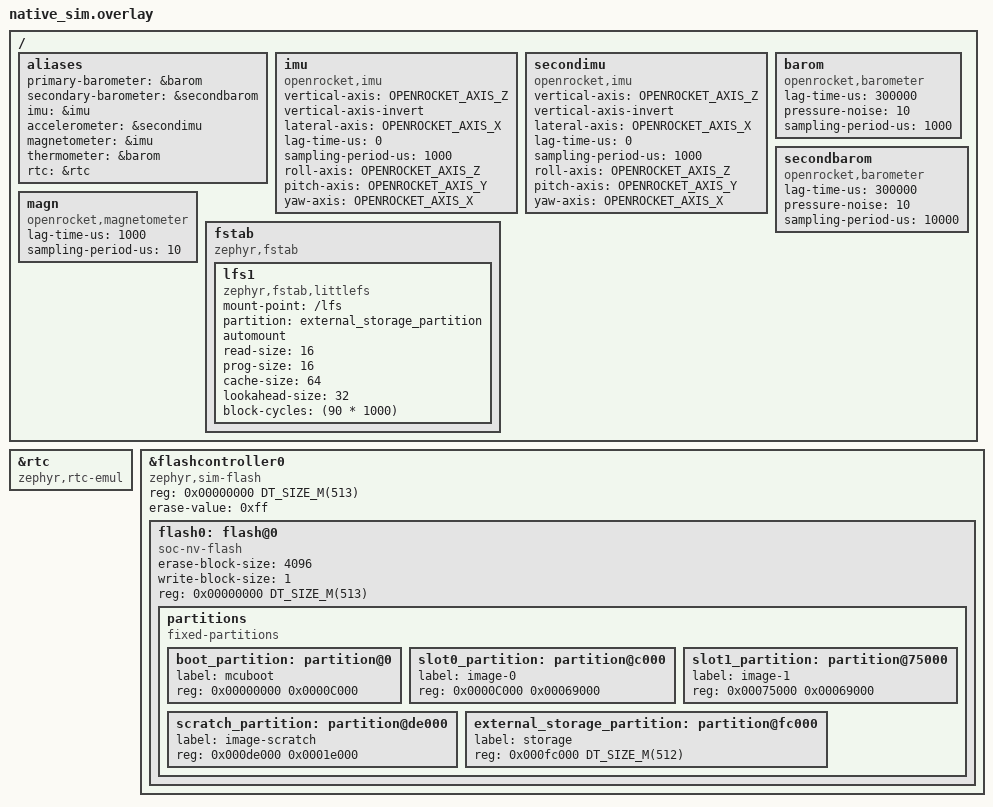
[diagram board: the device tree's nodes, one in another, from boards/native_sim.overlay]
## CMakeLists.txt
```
#-------------------------------------------------------------------------------
# Backplane Sensor Module Application
#
# Copyright (c) 2023 Launch Initiative
# SPDX-License-Identifier: Apache-2.0

set(FSW_ROOT ${CMAKE_CURRENT_SOURCE_DIR}/../../..)
include(${FSW_ROOT}/cmake/Autocoders.cmake)
include(${FSW_ROOT}/cmake/Snippets.cmake)

list(APPEND SNIPPETS
"bpl-networking"
"cpp"
)

AddSnippets(${SNIPPETS})


list(APPEND CONF_FILE ${CMAKE_CURRENT_SOURCE_DIR}/core.conf)

if (DEBUG)
    message(STATUS "Adding debug configuration")
    AddDebugSnippets()
    list(APPEND CONF_FILE ${CMAKE_CURRENT_SOURCE_DIR}/debug.conf)
endif ()

if (BOARD STREQUAL "native_sim")
    if (UNIX AND NOT APPLE)
        message(STATUS "Adding simulation configuration")
        AddSimSnippets()
        list(APPEND CONF_FILE ${CMAKE_CURRENT_SOURCE_DIR}/sim.conf)
    else ()
        message(FATAL_ERROR "Simulation is only supported on Linux systems")
    endif ()
endif ()

cmake_minimum_required(VERSION 3.13.1)
find_package(Zephyr REQUIRED HINTS $ENV{ZEPHYR_BASE})

project(sensor-module LANGUAGES C CXX)

FILE(GLOB SOURCES src/*.c src/*.cpp)
target_include_directories(app PRIVATE include)
target_sources(app PRIVATE ${SOURCES})

AutocodeTypes(${CMAKE_SOURCE_DIR}/ac/types.yaml)
AutocodeNetworkDefinitions()
add_dependencies(app ac_net_defs ac_types)
```

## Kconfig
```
# Copyright (c) 2024 Launch Initiative
# SPDX-License-Identifier: Apache-2.0

menu "Zephyr"
source "Kconfig.zephyr"
endmenu

module = APP_SENSOR_MODULE
module-str = APP_SENSOR_MODULE
source "subsys/logging/Kconfig.template.log_config"

config MODULE_ID
    int "Module ID number"
    default 1
    help
      The module ID to use as the fourth octet in the IP address.
```

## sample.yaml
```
sample:
  description: Sensor Module
  name: sensor-module
common:
  build_only: true
  integration_platforms:
    - sensor_module
tests:
  backplane.sensor_module.default: {}
# Disabled for now due to RAM constraints
#  backplane.sensor_module.debug:
#    extra_overlay_confs:
#      - sim.conf
```

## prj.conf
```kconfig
# Copyright (c) 2024 RIT Launch Initiative
# SPDX-License-Identifier: Apache-2.0

# CPP
CONFIG_CPP=y
CONFIG_REQUIRES_FULL_LIBCPP=y
CONFIG_STD_CPP20=y

CONFIG_F_CORE=y
CONFIG_CBPRINTF_FP_SUPPORT=y

# Filesystem
CONFIG_FILE_SYSTEM=y
CONFIG_FLASH_MAP=y
CONFIG_FLASH=y
# OS
CONFIG_POLL=y
CONFIG_MAIN_STACK_SIZE=1024
CONFIG_STACK_USAGE=y

CONFIG_TIMESLICING=y
CONFIG_TIMESLICE_SIZE=50000
CONFIG_TIMESLICE_PRIORITY=0
CONFIG_THREAD_STACK_INFO=y

CONFIG_DYNAMIC_THREAD=y
# Max stack size for dynamic threads
CONFIG_DYNAMIC_THREAD_STACK_SIZE=512
CONFIG_DYNAMIC_THREAD_POOL_SIZE=4
CONFIG_LOG=y

# Networking
CONFIG_NETWORKING=y
CONFIG_NET_ARP_TABLE_SIZE=4
CONFIG_NET_CONTEXT_RCVTIMEO=y
CONFIG_NET_DEFAULT_IF_ETHERNET=y
CONFIG_NET_DRIVERS=y
CONFIG_NET_IPV4=y
CONFIG_NET_IPV6=n
CONFIG_NET_L2_ETHERNET=y
CONFIG_NET_L2_ETHERNET_MGMT=y
CONFIG_NET_MAX_CONN=10
CONFIG_NET_SOCKETS=y
CONFIG_NET_STATISTICS=y

# RNG (Needed for networking)
CONFIG_ENTROPY_GENERATOR=y
CONFIG_TEST_RANDOM_GENERATOR=y # TODO: See if its worth using STM32 HW RNG to remove warning

# IO
CONFIG_I2C=y
CONFIG_SPI=y
CONFIG_SENSOR=y
```

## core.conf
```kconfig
# Copyright (c) 2024 RIT Launch Initiative
# SPDX-License-Identifier: Apache-2.0

CONFIG_F_CORE=y
CONFIG_F_CORE_DEVICE=y
CONFIG_F_CORE_SENSOR=y
CONFIG_F_CORE_NET=y
CONFIG_F_CORE_OS=y
CONFIG_F_CORE_UTILS=y

CONFIG_CBPRINTF_FP_SUPPORT=y

# OS
CONFIG_POLL=y
CONFIG_MAIN_STACK_SIZE=2048
CONFIG_STACK_USAGE=y

CONFIG_TIMESLICING=y
CONFIG_TIMESLICE_SIZE=20
CONFIG_TIMESLICE_PRIORITY=0
CONFIG_THREAD_STACK_INFO=y

CONFIG_DYNAMIC_THREAD=y
# Max stack size for dynamic threads
CONFIG_DYNAMIC_THREAD_STACK_SIZE=4096
CONFIG_DYNAMIC_THREAD_POOL_SIZE=3
CONFIG_LOG=y
CONFIG_EVENTS=y

# IO
CONFIG_I2C=y
CONFIG_SPI=y
CONFIG_SENSOR=y
```

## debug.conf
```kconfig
# Copyright (c) 2024 Launch Initiative
# SPDX-License-Identifier: Apache-2.0

CONFIG_APP_SENSOR_MODULE_LOG_LEVEL_DBG=y
```

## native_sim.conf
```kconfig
# Sensors
CONFIG_OPENROCKET_LOG_LEVEL_DBG=y
CONFIG_OPENROCKET_SENSORS=y
CONFIG_OPENROCKET_DATA_FILE="../../../data/orksim_csv/omen.csv"
CONFIG_OPENROCKET_MS_BEFORE_LAUNCH=1000
CONFIG_OPENROCKET_SCALAR_TYPE_DOUBLE=y
CONFIG_OPENROCKET_EVENT_LOG=y
CONFIG_OPENROCKET_IMU=y
CONFIG_OPENROCKET_BAROMETER=y
```

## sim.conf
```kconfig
# Sensors
CONFIG_OPENROCKET_SENSORS=y
CONFIG_OPENROCKET_DATA_FILE="../../../data/orksim_csv/l1.csv"
CONFIG_OPENROCKET_SCALAR_TYPE_DOUBLE=y
CONFIG_OPENROCKET_EVENT_LOG=y
CONFIG_OPENROCKET_IMU=y
CONFIG_OPENROCKET_BAROMETER=y
CONFIG_OPENROCKET_MANUAL_LAUNCH_TRIGGER=y

CONFIG_RTC=y
CONFIG_RTC_EMUL=y

CONFIG_SYS_CLOCK_TICKS_PER_SEC=10000
CONFIG_DEBUG=y
```

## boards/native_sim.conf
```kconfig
# Sensors
#CONFIG_OPENROCKET_NOISE=y
#CONFIG_OPENROCKET_NOISE_SEED=0

CONFIG_OPENROCKET_SENSORS=y
CONFIG_OPENROCKET_DATA_FILE="../../../data/orksim_csv/omen.csv"
CONFIG_OPENROCKET_MS_BEFORE_LAUNCH=150000
CONFIG_OPENROCKET_SCALAR_TYPE_DOUBLE=y
CONFIG_OPENROCKET_EVENT_LOG=y
CONFIG_OPENROCKET_IMU=y
CONFIG_OPENROCKET_BAROMETER=y

CONFIG_RTC_EMUL=y
```

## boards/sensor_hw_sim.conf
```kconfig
# Sensors
#CONFIG_OPENROCKET_NOISE=y
#CONFIG_OPENROCKET_NOISE_SEED=0

CONFIG_OPENROCKET_SENSORS=y
CONFIG_OPENROCKET_DATA_FILE="../../../data/orksim_csv/l1.csv"
CONFIG_OPENROCKET_MS_BEFORE_LAUNCH=10000
CONFIG_OPENROCKET_SCALAR_TYPE_DOUBLE=y
CONFIG_OPENROCKET_EVENT_LOG=y
CONFIG_OPENROCKET_IMU=y
CONFIG_OPENROCKET_BAROMETER=y
CONFIG_OPENROCKET_MANUAL_LAUNCH_TRIGGER=y

CONFIG_CONSOLE=y
CONFIG_CONSOLE_SUBSYS=y
CONFIG_SERIAL=y
CONFIG_UART_CONSOLE=y
```

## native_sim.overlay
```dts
/ {
	aliases {
		primary-barometer = &barom;
		secondary-barometer = &barom;
		imu = &imu;
		accelerometer = &imu;
		magnetometer = &imu;
		thermometer = &barom;
	};

    imu: imu {
        status = "okay";
        compatible = "openrocket,imu";
        vertical-axis = "OPENROCKET_AXIS_Z";
        vertical-axis-invert;
        lateral-axis = "OPENROCKET_AXIS_X";
        lag-time-us = <1000>;
        sampling-period-us = <10>;

        roll-axis = "OPENROCKET_AXIS_Z";
        pitch-axis = "OPENROCKET_AXIS_Y";
        yaw-axis = "OPENROCKET_AXIS_X";
    };

    barom: barom {
        status = "okay";
        compatible = "openrocket,barometer";
        lag-time-us = <1000>;
        sampling-period-us = <10>;
    };
};
```

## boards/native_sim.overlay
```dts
/ {
	aliases {
		primary-barometer = &barom;
		secondary-barometer = &secondbarom;
		imu = &imu;
		accelerometer = &secondimu;
		magnetometer = &imu;
		thermometer = &barom;
		rtc = &rtc;
	};

    imu: imu {
        status = "okay";
        compatible = "openrocket,imu";
        vertical-axis = "OPENROCKET_AXIS_Z";
        vertical-axis-invert;
        lateral-axis = "OPENROCKET_AXIS_X";
        lag-time-us = <0>;
        sampling-period-us = <1000>;

        roll-axis = "OPENROCKET_AXIS_Z";
        pitch-axis = "OPENROCKET_AXIS_Y";
        yaw-axis = "OPENROCKET_AXIS_X";
    };


    secondimu: secondimu {
        status = "okay";
        compatible = "openrocket,imu";
        vertical-axis = "OPENROCKET_AXIS_Z";
        vertical-axis-invert;
        lateral-axis = "OPENROCKET_AXIS_X";
        lag-time-us = <0>;
        sampling-period-us = <1000>;

        roll-axis = "OPENROCKET_AXIS_Z";
        pitch-axis = "OPENROCKET_AXIS_Y";
        yaw-axis = "OPENROCKET_AXIS_X";
    };


    barom: barom {
        status = "okay";
        compatible = "openrocket,barometer";
        lag-time-us = <300000>; // from grim analysis
		pressure-noise = <10>;
        sampling-period-us = <1000>;
    };

    secondbarom: secondbarom {
        status = "okay";
        compatible = "openrocket,barometer";
        lag-time-us = <300000>; // from grim analysis
		pressure-noise = <10>;
		sampling-period-us = <10000>;
    };

    magn: magn {
        status = "okay";
        compatible = "openrocket,magnetometer";
        lag-time-us = <1000>;
		sampling-period-us = <10>;
    };

	fstab {
		compatible = "zephyr,fstab";
		lfs1: lfs1 {
			compatible = "zephyr,fstab,littlefs";
			mount-point = "/lfs";
			partition = <&external_storage_partition>;
			automount;

			// the binding reccomends defaults for these
			read-size = <16>;
			prog-size = <16>;
			cache-size = <64>; // may need to grow for optimization
			lookahead-size = <32>;
			block-cycles = <(90 * 1000)>;
			// the datasheet gives 100K P-E cycles
			// NOTE: this seems to default to 512 for the mounted filesystem
			// anyway
		};
	};
};

&rtc {
	status = "okay";
	compatible = "zephyr,rtc-emul";
};

&flashcontroller0 {
	status = "okay";
	compatible = "zephyr,sim-flash";
	reg = <0x00000000 DT_SIZE_M(513)>;

	#address-cells = <1>;
	#size-cells = <1>;
	erase-value = <0xff>;

	flash0: flash@0 {
		status = "okay";
		compatible = "soc-nv-flash";
		erase-block-size = <4096>;
		write-block-size = <1>;
		reg = <0x00000000 DT_SIZE_M(513)>; // builtin stuff + external flash simulation

		partitions {
			compatible = "fixed-partitions";
			#address-cells = <1>;
			#size-cells = <1>;

			boot_partition: partition@0 {
				label = "mcuboot";
				reg = <0x00000000 0x0000C000>;
			};
			slot0_partition: partition@c000 {
				label = "image-0";
				reg = <0x0000C000 0x00069000>;
			};
			slot1_partition: partition@75000 {
				label = "image-1";
				reg = <0x00075000 0x00069000>;
			};
			scratch_partition: partition@de000 {
				label = "image-scratch";
				reg = <0x000de000 0x0001e000>;
			};
			external_storage_partition: partition@fc000 {
				label = "storage";
				reg = <0x000fc000 DT_SIZE_M(512)>;
			};
		};
	};
};
```

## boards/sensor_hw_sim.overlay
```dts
/ {
	aliases {
		primary-barometer = &barom;
		secondary-barometer = &secondbarom;
		imu = &imu;
		accelerometer = &secondimu;
		magnetometer = &imu;
		thermometer = &barom;
	};

    imu: imu {
        status = "okay";
        compatible = "openrocket,imu";
        vertical-axis = "OPENROCKET_AXIS_Z";
        vertical-axis-invert;
        lateral-axis = "OPENROCKET_AXIS_X";
        lag-time-us = <0>;
        sampling-period-us = <1000>;

        roll-axis = "OPENROCKET_AXIS_Z";
        pitch-axis = "OPENROCKET_AXIS_Y";
        yaw-axis = "OPENROCKET_AXIS_X";
    };


    secondimu: secondimu {
        status = "okay";
        compatible = "openrocket,imu";
        vertical-axis = "OPENROCKET_AXIS_Z";
        vertical-axis-invert;
        lateral-axis = "OPENROCKET_AXIS_X";
        lag-time-us = <0>;
        sampling-period-us = <1000>;

        roll-axis = "OPENROCKET_AXIS_Z";
        pitch-axis = "OPENROCKET_AXIS_Y";
        yaw-axis = "OPENROCKET_AXIS_X";
    };


    barom: barom {
        status = "okay";
        compatible = "openrocket,barometer";
        lag-time-us = <300000>; // from grim analysis
		pressure-noise = <10>;
        sampling-period-us = <1000>;
    };

    secondbarom: secondbarom {
        status = "okay";
        compatible = "openrocket,barometer";
        lag-time-us = <300000>; // from grim analysis
		pressure-noise = <10>;
		sampling-period-us = <10000>;
    };

    magn: magn {
        status = "okay";
        compatible = "openrocket,magnetometer";
        lag-time-us = <1000>;
		sampling-period-us = <10>;
    };
};
```

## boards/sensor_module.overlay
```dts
/ {
	aliases {
		primary-barometer = &ms5611;
		secondary-barometer = &bmp388;
		imu = &lsm6dsl;
		accelerometer = &adxl375;
		magnetometer = &lis3mdl;
		thermometer = &tmp117;

		rs485-uart = &uart5;
		rs485-de = &de_hack;
		rtc = &rtc;
	};
};
```

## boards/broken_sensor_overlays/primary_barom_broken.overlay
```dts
&barom{
    broken;
};
```

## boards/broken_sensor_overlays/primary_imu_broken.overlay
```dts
&imu{
    broken;
};
```

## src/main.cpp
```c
/*
* Copyright (c) 2024 RIT Launch Initiative
 *
 * SPDX-License-Identifier: Apache-2.0
 */
#include "c_sensor_module.h"

#include <f_core/os/n_rtos.h>
#ifdef CONFIG_ARCH_POSIX
#include <nsi_main.h>
#include <signal.h>
#endif

#ifdef CONFIG_ARCH_POSIX
static volatile sig_atomic_t shutdownRequested = 0;

static void NativeSimSignalHandler(int) { shutdownRequested = 1; }
#endif

int main() {
    static CSensorModule sensorModule{};

    sensorModule.AddTenantsToTasks();
    sensorModule.AddTasksToRtos();
    sensorModule.SetupCallbacks();

    NRtos::StartRtos();

#ifdef CONFIG_ARCH_POSIX
    signal(SIGINT, NativeSimSignalHandler);
    signal(SIGTERM, NativeSimSignalHandler);

    while (!shutdownRequested) {
        k_sleep(K_MSEC(100));
    }

    NRtos::StopRtos();
    sensorModule.Cleanup();
    nsi_exit(0);
#endif

    return 0;
}
```

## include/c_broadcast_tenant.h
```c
#ifndef C_BROADCAST_TENANT_H
#define C_BROADCAST_TENANT_H

#include <f_core/os/c_tenant.h>

#include <f_core/net/network/c_ipv4.h>
#include <f_core/net/transport/c_udp_socket.h>

class CBroadcastTenant : public CTenant {
public:
    explicit CBroadcastTenant(const char* name, const char *ipStr, const uint16_t srcPort, const uint16_t dstPort)
        : CTenant(name), ip(CIPv4{ipStr}), udp(CUdpSocket{ip, srcPort, dstPort})
    {
    }

    ~CBroadcastTenant() override = default;

    void Startup() override;

    void PostStartup() override;

    void Run() override;

private:
    CIPv4 ip;
    CUdpSocket udp;
};



#endif //C_BROADCAST_TENANT_H
```

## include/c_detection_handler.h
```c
#pragma once

// All in one holder for all the detection we do
#include "f_core/utils/debouncer.hpp"
#include "f_core/utils/linear_fit.hpp"
#include "flight.hpp"

#include <f_core/messaging/c_message_port.h>
#include <f_core/n_alerts.h>
#include <n_autocoder_types.h>

class CDetectionHandler {
  public:
    struct SensorWorkings {
        bool primaryAccOk;
        bool secondaryAccOk;
        bool primaryBarometerOk;
        bool secondaryBarometerOk;
    };

    static constexpr std::size_t BAROM_VELOCITY_FINDER_WINDOW_SIZE = 10; // @100hz, 0.1 second window.
    using VelocityFinder = CRollingSum<LinearFitSample<double>, BAROM_VELOCITY_FINDER_WINDOW_SIZE>;

    // Boost Detectors
    using AccBoostDetector = CDebouncer<ThresholdDirection::Over, double>;
    using BaromBoostDetector = CDebouncer<ThresholdDirection::Over, double>;

    using BaromNoseoverDetector = CDebouncer<ThresholdDirection::Under, double>;
    using BaromGroundDetector = CDebouncer<ThresholdDirection::Under, double>;
    CDetectionHandler(SensorModulePhaseController& controller, CMessagePort<NAlerts::AlertPacket>& alertMessagePort);

    SensorModulePhaseController& controller;
    AccBoostDetector primaryImuBoostSquaredDetector;
    AccBoostDetector secondaryImuBoostSquaredDetector;

    VelocityFinder primaryBaromVelocityFinder;
    VelocityFinder secondaryBaromVelocityFinder;

    BaromNoseoverDetector primaryBaromNoseoverDetector;
    BaromNoseoverDetector secondaryBaromNoseoverDetector;

    BaromGroundDetector primaryBaromGroundDetector;
    BaromGroundDetector secondaryBaromGroundDetector;

    static constexpr uint64_t BOOST_NOT_YET_HAPPENED = ~0;
    uint64_t boost_detected_time = BOOST_NOT_YET_HAPPENED;

    static constexpr uint32_t alertResendCycles = 20;
    uint32_t boostAlertResendsRemaining = 0;
    uint32_t landedAlertResendsRemaining = alertResendCycles;

    // Rebroadcast the landed alert once GroundHit occurs. Covers both the
    // barometer and timer paths, and survives UDP loss like the boost alert.
    void ServiceLandedAlert();

    /**
     * Process sensor information 
     * @param uptime uptime in milliseconds of the system
     * @param data sensor data from Sensing Tenant
     * @param workings a description of which sensors were read correctly
     */
    void HandleData(const uint64_t uptime, const NTypes::SensorData& data, const SensorWorkings& workings);

    /**
     * Process sensor information before boost has been detected
     * @param t_plus_ms milliseconds since boost
     * @param data sensor data from Sensing Tenant
     * @param workings a description of which sensors were read correctly
     */
    void HandleBoost(const uint64_t uptime, const NTypes::SensorData& data, const SensorWorkings& workings);
    /**
     * Process sensor information before the noseover has been reached
     * @param t_plus_ms milliseconds since boost
     * @param data sensor data from Sensing Tenant
     * @param workings a description of which sensors were read correctly
     */
    void HandleNoseover(const uint32_t t_plus_ms, const NTypes::SensorData& data, const SensorWorkings& workings);
    /**
     * Process sensor information before the ground has been hit
     * @param t_plus_ms milliseconds since boost
     * @param data sensor data from Sensing Tenant
     * @param workings a description of which sensors were read correctly
     */
    void HandleGround(const uint32_t t_plus_ms, const NTypes::SensorData& data, const SensorWorkings& workings);

    bool FlightOccurring() {
        // int uptime = k_uptime_get();
        // static constexpr int START_TIME = 10000; // 10 seconds
        // static constexpr int END_TIME = 30000; // 30 seconds

        // return START_TIME <= uptime && uptime <= END_TIME;
        return controller.HasEventOccurred(Events::Boost) && !controller.HasEventOccurred(Events::GroundHit);
    }

    bool FlightFinished() {
        // int uptime = k_uptime_get();
        // return uptime >= 30000;

        return controller.HasEventOccurred(Events::GroundHit);
    }

    /**
     * Whether or not the phase detector needs more data. True before ground hit, false after
     * @return true if the detection system wants more data, false if we're all finished
     */
    bool ContinueCollecting();

  private:
    static constexpr NAlerts::AlertPacket boostNotification = {'L', 'A', 'U', 'N', 'C', 'H', 'b'};
    static constexpr NAlerts::AlertPacket noseoverNotification = {'L', 'A', 'U', 'N', 'C', 'H', 'n'};
    static constexpr NAlerts::AlertPacket landedNotification = {'L', 'A', 'U', 'N', 'C', 'H', 'l'};

    CMessagePort<NAlerts::AlertPacket>& alertMessagePort;
};
```

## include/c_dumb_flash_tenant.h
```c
#ifndef C_DUMB_FLASH_TENANT_H
#define C_DUMB_FLASH_TENANT_H
#include <f_core/messaging/c_message_port.h>
#include <f_core/os/c_runnable_tenant.h>
#include <f_core/os/c_tenant.h>
#include <f_core/utils/c_soft_timer.h>
#include <n_autocoder_types.h>
#include <zephyr/drivers/flash.h>
#include <zephyr/logging/log.h>

class CDumbFlashTenant : public CRunnableTenant {
  public:
    static constexpr size_t ERASE_SIZE = 4096;
    static constexpr size_t ELEMENT_SIZE = sizeof(NTypes::TimestampedSensorData);
    using Element = NTypes::TimestampedSensorData;

    CDumbFlashTenant(const char *name, const struct device *device, size_t flash_offset, size_t partition_size,
                     CMessagePort<NTypes::TimestampedSensorData> &port);

    void Startup() override;
    void Run();

  private:
    const struct device *device;
    size_t flash_offset;
    size_t offset_into_partition = 0;
    size_t partition_size;
    CMessagePort<NTypes::TimestampedSensorData> &port;
};

#endif
```

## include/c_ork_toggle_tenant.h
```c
#pragma once

#include <f_core/net/network/c_ipv4.h>
#include <f_core/net/transport/c_udp_socket.h>
#include <f_core/os/c_runnable_tenant.h>

class COrkToggleTenant : public CRunnableTenant {
  public:
    /**
     * @param name Tenant name
     * @param ipStr IP address to bind the UDP socket to
     * @param port UDP port used to receive launch trigger packets
     */
    COrkToggleTenant(const char* name, const char* ipStr, int port);

    /**
     * See parent docs
     */
    void Run() override;

  private:
    CUdpSocket udp;
    int port;
};
```

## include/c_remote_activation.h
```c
#ifndef C_REMOTE_ACTIVATION_TENANT_H
#define C_REMOTE_ACTIVATION_TENANT_H

#include <f_core/net/network/c_ipv4.h>
#include <f_core/net/transport/c_udp_socket.h>
#include <f_core/os/c_tenant.h>
#include <zephyr/drivers/gpio.h>

class CRemoteActivationTenant : public CTenant {
public:
    explicit CRemoteActivationTenant(const char* name, const gpio_dt_spec &pin)
        : CTenant(name), ip(CIPv4{"10.3.2.1"}), udp(CUdpSocket{ip, commandPort, commandPort}), pin(pin)
    {
    }

    ~CRemoteActivationTenant() override = default;

    void Startup() override;

    void PostStartup() override;

    void Run() override;

private:
    static constexpr uint16_t commandPort = 13001;

    CIPv4 ip;
    CUdpSocket udp;
    const gpio_dt_spec &pin;
};


#endif //C_REMOTE_ACTIVATION_TENANT_H
```

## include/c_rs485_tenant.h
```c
#ifndef C_RS485_TENANT_H
#define C_RS485_TENANT_H

#include <f_core/net/device/c_rs485.h>
#include <f_core/os/c_tenant.h>

#include <zephyr/drivers/gpio.h>


class CRs485Tenant : public CTenant {
public:
  CRs485Tenant(const char* name)
    : CTenant(name)
  {
  }

  void Startup() override;

  void PostStartup() override;

  void Run() override;

private:
  // CRs485 &rs485{DEVICE_DT_GET(DT_ALIAS(rs485_uart)), GPIO_DT_SPEC_GET(de_hack, leds)};;

};



#endif //C_RS485_TENANT_H
```

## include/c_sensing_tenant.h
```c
#pragma once

#include "c_detection_handler.h"
#include "f_core/device/c_rtc.h"

#include <array>
#include <f_core/device/sensor/c_accelerometer.h>
#include <f_core/device/sensor/c_barometer.h>
#include <f_core/device/sensor/c_gyroscope.h>
#include <f_core/device/sensor/c_magnetometer.h>
#include <f_core/device/sensor/c_temperature_sensor.h>
#include <f_core/messaging/c_message_port.h>
#include <f_core/os/c_runnable_tenant.h>
#include <n_autocoder_types.h>
#include <zephyr/device.h>

class CSensorDevice;

class CSensingTenant : public CRunnableTenant {
  public:
    explicit CSensingTenant(const char *name, CMessagePort<NTypes::SensorData> &dataToBroadcast,
                            CMessagePort<NTypes::LoRaBroadcastSensorData> &downlinkDataToBroadcast,
                            CMessagePort<NTypes::TimestampedSensorData> &dataToLog, CDetectionHandler &handler);
    ~CSensingTenant() override = default;

    void Startup() override;
    void PostStartup() override;
    void Run() override;

  private:
    CMessagePort<NTypes::SensorData> &dataToBroadcast;
    CMessagePort<NTypes::TimestampedSensorData> &dataToLog;
    CMessagePort<NTypes::LoRaBroadcastSensorData> &dataToDownlink;

    CDetectionHandler &detectionHandler;
    // Sensor instances
    CAccelerometer imuAccelerometer;
    CGyroscope imuGyroscope;
    CBarometer primaryBarometer;
    CBarometer secondaryBarometer;
    CAccelerometer accelerometer;
    CTemperatureSensor thermometer;
    CMagnetometer magnetometer;

    std::array<CSensorDevice *, 7> sensors;

    CRtc rtc{*DEVICE_DT_GET(DT_ALIAS(rtc))};

    void sendDownlinkData(const NTypes::SensorData &data);

    void calibrateADXL375();
};
```

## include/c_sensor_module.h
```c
#pragma once

#include "c_sensing_tenant.h"
#include "flight.hpp"
#ifdef CONFIG_OPENROCKET_MANUAL_LAUNCH_TRIGGER
#include "c_ork_toggle_tenant.h"
#endif

// F-Core Includes
#include <f_core/c_project_configuration.h>
#include <f_core/device/c_rtc.h>
#include <f_core/messaging/c_message_port.h>
#include <f_core/n_alerts.h>
#include <f_core/net/application/c_udp_broadcast_tenant.h>
#include <f_core/os/c_task.h>
#include <f_core/os/flight_log.hpp>
#include <f_core/os/tenants/c_datalogger_tenant.h>
#include <n_autocoder_network_defs.h>
#include <n_autocoder_types.h>
#include <zephyr/fs/littlefs.h>

class CSensorModule : public CProjectConfiguration {
  public:
    /**
     * Constructor
     */
    CSensorModule();

    /**
     * See parent docs
     */
    void AddTenantsToTasks() override;

    /**
     * See parent docs
     */
    void AddTasksToRtos() override;

    /**
     * See parent docs
     */
    void SetupCallbacks() override;

    /**
    * Cleanup
    */
    void Cleanup() { dataLoggerTenant.Cleanup(); }

  private:
    std::string ipAddrStr = CREATE_IP_ADDR(NNetworkDefs::SENSOR_MODULE_IP_ADDR_BASE, 1, CONFIG_MODULE_ID);
    const char* sntpServerAddr = "10.2.1.1"; // TODO: Maybe we should look into hostnames?

    static constexpr int telemetryBroadcastPort = NNetworkDefs::SENSOR_MODULE_TELEMETRY_PORT;
    static constexpr int telemetryDownlinkPort = NNetworkDefs::SENSOR_MODULE_DOWNLINK_DATA_PORT;
    static constexpr int alertPort = NNetworkDefs::ALERT_PORT;
#ifdef CONFIG_OPENROCKET_MANUAL_LAUNCH_TRIGGER
    static constexpr int orkLaunchTriggerPort = NNetworkDefs::SENSOR_MODULE_ORK_LAUNCH_TRIGGER_PORT;
#endif

    // Devices
    CRtc rtc{*DEVICE_DT_GET(DT_ALIAS(rtc))};

    // Message Ports
    CMessagePort<NTypes::SensorData>& sensorDataBroadcastMessagePort;
    CMessagePort<NTypes::LoRaBroadcastSensorData>& downlinkMessagePort;
    CMessagePort<NTypes::TimestampedSensorData>& sensorDataLogMessagePort;
    CMessagePort<NAlerts::AlertPacket>& alertMessagePort;

    CFlightLog flight_log;
    SensorModulePhaseController controller{sourceNames, eventNames, timerEvents, deciders, NULL};
    CDetectionHandler detectionHandler{controller, alertMessagePort};

    // Tenants
    CSensingTenant sensingTenant{"Sensing Tenant", sensorDataBroadcastMessagePort, downlinkMessagePort,
                                 sensorDataLogMessagePort, detectionHandler};
    CUdpBroadcastTenant<NTypes::SensorData> broadcastTenant{"Broadcast Tenant", ipAddrStr.c_str(),
                                                            telemetryBroadcastPort, telemetryBroadcastPort,
                                                            sensorDataBroadcastMessagePort};
    CUdpBroadcastTenant<NTypes::LoRaBroadcastSensorData> downlinkTelemTenant{
        "Telemetry Downlink Tenant", ipAddrStr.c_str(), telemetryDownlinkPort, telemetryDownlinkPort,
        downlinkMessagePort};
    CUdpBroadcastTenant<NAlerts::AlertPacket> udpAlertTenant{"UDP Alert Tenant", ipAddrStr.c_str(), alertPort,
                                                             alertPort, alertMessagePort};
    CDataLoggerTenant<NTypes::TimestampedSensorData> dataLoggerTenant{"Data Logger Tenant",
                                                                      "/lfs/sensor_module_data.bin",
                                                                      LogMode::Growing,
                                                                      0,
                                                                      sensorDataLogMessagePort,
                                                                      K_SECONDS(3),
                                                                      64};
#ifdef CONFIG_OPENROCKET_MANUAL_LAUNCH_TRIGGER
    COrkToggleTenant orkLaunchTriggerTenant{"Ork Toggle Tenant", ipAddrStr.c_str(), orkLaunchTriggerPort};
#endif

    // Tasks
    CTask networkTask{"Networking Task", 15, 3072, 10};
    CTask sensingTask{"Sensing Task", 14, 4096, 10};
    CTask dataLogTask{"Data Logging Task", 13, 4096, 5};
};
```

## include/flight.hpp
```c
#ifndef SENSOR_MOD_FLIGHT_H_
#define SENSOR_MOD_FLIGHT_H_
#include <array>
#include <cstdint>
#include <f_core/flight/c_phase_controller.h>

// Boost
static constexpr double boostThresholdMPerS2 = 4 * 9.8; // m/s^2
static constexpr uint32_t boostTimeThreshold = 250;     // ms

// Noseover
static constexpr double noseoverVelocityThresshold = 10; // ft/s
static constexpr uint32_t noseoverTimeThreshold = 250;   // ms

// Ground
static constexpr double groundVelocityThreshold = 10;  // ft/s
static constexpr uint32_t groundTimeThreshold = 10000; // ms (10s)

enum Events : uint8_t { Boost, NoseoverLockout, Noseover, GroundHit, NumEvents };
inline constexpr std::array<const char *, Events::NumEvents> eventNames = {
    "Boost",
    "NoseoverLockout",
    "Noseover",
    "GroundHit",
};

/**
 * Sources of flight events
 */
enum Sources : uint8_t { LowGImu, HighGImu, BaromBMP, BaromMS5611, NoseoverLockoutTimer, FullFlightTimer, NumSources };
inline constexpr std::array<const char *, Sources::NumSources> sourceNames = {
    "LowGIMU (LSM6DSL)", "HighGIMU (ADXL375)", "BaromBMP388", "BaromMS5611", "Noseover Lockout", "Full Flight Timer"};

inline constexpr std::size_t numTimerEvents = 3;
using SensorModulePhaseController =
    CPhaseController<Events, Events::NumEvents, Sources, Sources::NumSources, numTimerEvents>;

/**
 * Special events triggered not by sensors but by timers between phases
 */
inline std::array<SensorModulePhaseController::TimerEvent, numTimerEvents> timerEvents = {
    // We dont want to accidentally detect noseover when still burning and the baroms are lagging.
    // Adds a lockout timer so even if our sensors say we nosed over, don't trust them until we've had time to slowdown
    SensorModulePhaseController::TimerEvent{
        .start = Events::Boost,
        .event = Events::NoseoverLockout,
        .time = K_SECONDS(3),
        .source = Sources::NoseoverLockoutTimer,
    },
    // We know our entire flight will not last longer than X seconds even if we main at apogee.
    //This stops us from overwriting flight data if we don't detect the end
    SensorModulePhaseController::TimerEvent{
        .start = Events::Boost,
        .event = Events::GroundHit,
        .time = K_SECONDS(100),
        .source = Sources::FullFlightTimer,
    },

};

/**
 * Functions for merging the different sources of events
 * 
 * silly immediately invoked lambda because c++ doesn't support designated array initializers :(
 * still constexpr tho which is nice
 */
inline constexpr std::array<SensorModulePhaseController::DecisionFunc, Events::NumEvents> deciders = [] {
    std::array<SensorModulePhaseController::DecisionFunc, Events::NumEvents> arr = {nullptr};

    // Boosting (when one of our sensors says go)
    arr[Events::Boost] = [](SensorModulePhaseController::SourceStates states) -> bool {
        return (states[Sources::LowGImu] || states[Sources::HighGImu] || states[Sources::BaromBMP] ||
                states[Sources::BaromMS5611]);
    };

    // NoseoverLockout
    arr[Events::NoseoverLockout] = [](SensorModulePhaseController::SourceStates states) -> bool {
        return states[Sources::NoseoverLockoutTimer];
    };

    // Noseover
    arr[Events::Noseover] = [](SensorModulePhaseController::SourceStates states) -> bool {
        return states[Sources::BaromBMP] || states[Sources::BaromMS5611];
    };

    // On the ground
    arr[Events::GroundHit] = [](SensorModulePhaseController::SourceStates states) -> bool {
        return states[Sources::BaromBMP] || states[Sources::BaromMS5611] || states[Sources::FullFlightTimer];
    };

    return arr;
}();

#endif
```

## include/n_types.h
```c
#ifndef N_TYPES_H
#define N_TYPES_H

#include <n_ac_types.h>

namespace NTypes {
struct __attribute__((packed)) SensorData {
    NTypes::BarometerData PrimaryBarometer;
    NTypes::BarometerData SecondaryBarometer;

    NTypes::AccelerometerData Acceleration;

    NTypes::AccelerometerData ImuAcceleration;
    NTypes::GyroscopeData ImuGyroscope;

    NTypes::MagnetometerData Magnetometer;

    NTypes::TemperatureData Temperature;
};

}

#endif //N_TYPES_H
```

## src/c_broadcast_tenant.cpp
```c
#include "c_broadcast_tenant.h"

#include <c_sensor_module.h>
#include <zephyr/logging/log.h>

LOG_MODULE_REGISTER(CBroadcastTenant);

extern k_msgq broadcastQueue;

void CBroadcastTenant::Startup() {
}

void CBroadcastTenant::PostStartup() {
}

void CBroadcastTenant::Run() {
    while (true) {
        CSensorModule::SensorData data{};
        if (k_msgq_get(&broadcastQueue, &data, K_FOREVER) == 0) {
            LOG_INF("Transmitting %d bytes of data", sizeof(CSensorModule::SensorData));
            udp.TransmitSynchronous(&data, sizeof(CSensorModule::SensorData));
        }
    }
}
```

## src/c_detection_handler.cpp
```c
#include "c_detection_handler.h"

#include <math.h>

double asl_from_pressure(double P_sta_kpa) {
    // Constants from https://www.weather.gov/media/epz/wxcalc/pressureAltitude.pdf
    static constexpr double standard_atmosphere_exponent = 0.190284;
    static constexpr double standard_atmosphere_factor = 145366.45;

    static constexpr double kpa_to_mbar = 10.0;
    static constexpr double sea_level_pressure_mbar = 1013.25;
    double P_sta_mbar = P_sta_kpa * kpa_to_mbar;

    return (1 - pow(P_sta_mbar / sea_level_pressure_mbar, standard_atmosphere_exponent)) * standard_atmosphere_factor;
}

CDetectionHandler::CDetectionHandler(SensorModulePhaseController& controller,
                                     CMessagePort<NAlerts::AlertPacket>& alertMessagePort)
    : controller(controller),
      primaryImuBoostSquaredDetector(boostTimeThreshold, boostThresholdMPerS2 * boostThresholdMPerS2),
      secondaryImuBoostSquaredDetector{boostTimeThreshold, boostThresholdMPerS2 * boostThresholdMPerS2},

      primaryBaromVelocityFinder{LinearFitSample<double>{0, 0}},
      secondaryBaromVelocityFinder{LinearFitSample<double>{0, 0}},

      primaryBaromNoseoverDetector{noseoverTimeThreshold, noseoverVelocityThresshold},
      secondaryBaromNoseoverDetector{noseoverTimeThreshold, noseoverVelocityThresshold},
      primaryBaromGroundDetector{groundTimeThreshold, groundVelocityThreshold},
      secondaryBaromGroundDetector{groundTimeThreshold, groundVelocityThreshold}, alertMessagePort(alertMessagePort) {}

bool CDetectionHandler::ContinueCollecting() { return !controller.HasEventOccurred(Events::GroundHit); }

void CDetectionHandler::HandleData(const uint64_t timestamp, const NTypes::SensorData& data,
                                   const SensorWorkings& sensor_states) {
    double t_seconds = static_cast<double>(timestamp) / 1000.0;

    double primary_barom_asl = asl_from_pressure(data.PrimaryBarometer.Pressure);
    double secondary_barom_asl = asl_from_pressure(data.SecondaryBarometer.Pressure);

    primaryBaromVelocityFinder.Feed(LinearFitSample(t_seconds, primary_barom_asl));
    secondaryBaromVelocityFinder.Feed(LinearFitSample(t_seconds, secondary_barom_asl));

    if (!controller.HasEventOccurred(Events::Boost)) {
        HandleBoost(timestamp, data, sensor_states);
        if (controller.HasEventOccurred(Events::Boost)) {
            // Boost confirmed so record for noseover and ground detection to 
            // measure time since boost and schedule rebroadcast of alert 
            boost_detected_time = timestamp;
            boostAlertResendsRemaining = alertResendCycles;
        }
    } else if (boostAlertResendsRemaining > 0) {
        alertMessagePort.Send(boostNotification);
        boostAlertResendsRemaining--;
    }
    // Don't worry about the rest until we've got boost
    if (!controller.HasEventOccurred(Events::Boost)) {
        return;
    }

    uint32_t t_plus_ms = timestamp - boost_detected_time - boostTimeThreshold;

    if (!controller.HasEventOccurred(Events::Noseover)) {
        HandleNoseover(t_plus_ms, data, sensor_states);
    }
    if (controller.HasEventOccurred(Events::Noseover) && !controller.HasEventOccurred(Events::GroundHit)) {
        HandleGround(t_plus_ms, data, sensor_states);
    }
}

void CDetectionHandler::HandleGround(const uint32_t t_plus_ms, const NTypes::SensorData& data,
                                     const SensorWorkings& sensor_states) {
    double primary_barom_velocity = 0;
    double secondary_barom_velocity = 0;

    bool primary_good = FindSlope(primaryBaromVelocityFinder, primary_barom_velocity);
    if (primary_good) {
        primaryBaromGroundDetector.Feed(t_plus_ms, fabs(primary_barom_velocity));
    }

    bool secondary_good = FindSlope(secondaryBaromVelocityFinder, secondary_barom_velocity);
    if (secondary_good) {
        secondaryBaromGroundDetector.Feed(t_plus_ms, fabs(secondary_barom_velocity));
    }

    if (primaryBaromGroundDetector.Passed() && sensor_states.primaryBarometerOk) {
        controller.SubmitEvent(Sources::BaromMS5611, Events::GroundHit);
    }
    if (secondaryBaromGroundDetector.Passed() && sensor_states.secondaryBarometerOk) {
        controller.SubmitEvent(Sources::BaromBMP, Events::GroundHit);
    }
}

void CDetectionHandler::ServiceLandedAlert() {
    if (controller.HasEventOccurred(Events::GroundHit) && landedAlertResendsRemaining > 0) {
        alertMessagePort.Send(landedNotification);
        landedAlertResendsRemaining--;
    }
}

void CDetectionHandler::HandleNoseover(const uint32_t t_plus_ms, const NTypes::SensorData& data,
                                       const SensorWorkings& sensor_states) {
    double primary_barom_velocity = 0;
    double secondary_barom_velocity = 0;

    bool primary_vel_good = FindSlope(primaryBaromVelocityFinder, primary_barom_velocity);
    if (primary_vel_good) {
        primaryBaromNoseoverDetector.Feed(t_plus_ms, primary_barom_velocity);
    }

    bool secondary_vel_good = FindSlope(secondaryBaromVelocityFinder, secondary_barom_velocity);
    if (secondary_vel_good) {
        secondaryBaromNoseoverDetector.Feed(t_plus_ms, secondary_barom_velocity);
    }

    if (primaryBaromNoseoverDetector.Passed() && controller.HasEventOccurred(Events::NoseoverLockout) &&
        sensor_states.primaryBarometerOk) {
        controller.SubmitEvent(Sources::BaromMS5611, Events::Noseover);
        alertMessagePort.Send(noseoverNotification);
    }
    if (secondaryBaromNoseoverDetector.Passed() && controller.HasEventOccurred(Events::NoseoverLockout) &&
        sensor_states.secondaryBarometerOk) {
        controller.SubmitEvent(Sources::BaromBMP, Events::Noseover);
        alertMessagePort.Send(noseoverNotification);
    }
}

void CDetectionHandler::HandleBoost(const uint64_t timestamp, const NTypes::SensorData& data,
                                    const SensorWorkings& sensor_states) {
    double primary_mag_squared_m_s2 = data.ImuAcceleration.X * data.ImuAcceleration.X +
                                      data.ImuAcceleration.Y * data.ImuAcceleration.Y +
                                      data.ImuAcceleration.Z * data.ImuAcceleration.Z;
    double secondary_mag_squared_m_s2 = data.Acceleration.X * data.Acceleration.X +
                                        data.Acceleration.Y * data.Acceleration.Y +
                                        data.Acceleration.Z * data.Acceleration.Z;

    primaryImuBoostSquaredDetector.Feed(timestamp, primary_mag_squared_m_s2);
    secondaryImuBoostSquaredDetector.Feed(timestamp, secondary_mag_squared_m_s2);

    if (primaryImuBoostSquaredDetector.Passed() && sensor_states.primaryAccOk) {
        controller.SubmitEvent(Sources::HighGImu, Events::Boost);
        alertMessagePort.Send(boostNotification);
    }
    if (secondaryImuBoostSquaredDetector.Passed() && sensor_states.secondaryAccOk) {
        controller.SubmitEvent(Sources::LowGImu, Events::Boost);
        alertMessagePort.Send(boostNotification);
    }
}
```
